AUTOSAR XML (schema 4-3-0)
package /MICROSAR/NvM_swc/DataTypes
  impl type NvM_RequestResultType: compu {0=NVM_REQ_OK, 1=NVM_REQ_NOT_OK, 2=NVM_REQ_PENDING, 3=NVM_REQ_INTEGRITY_FAILED, 4=NVM_REQ_BLOCK_SKIPPED, 5=NVM_REQ_NV_INVALIDATED, 6=NVM_REQ_CANCELED, 7=NVM_REQ_REDUNDANCY_FAILED, 8=NVM_REQ_RESTORED_FROM_ROM}, implementation-data-type=uint8
  impl type NvM_BlockIdType: range raw 1..32767, implementation-data-type=uint16
  impl type NvM_ServiceIdType: compu {6=NVM_READ_BLOCK, 7=NVM_WRITE_BLOCK, 8=NVM_RESTORE_BLOCK_DEFAULTS, 9=NVM_ERASE_BLOCK, 11=NVM_INVALIDATE_NV_BLOCK, 12=NVM_READ_ALL}, implementation-data-type=uint8
package /MICROSAR/NvM_swc/Interfaces
  6 x client server interface, all with is-service=true, service-kind=NON-VOLATILE-RAM-MANAGER:
    NvMAdministration
      operation SetBlockProtection: possible-error=NvMAdministration/E_NOT_OK
        arg ProtectionEnabled: type=boolean, direction=IN
      error E_NOT_OK: error-code=1
    NvMService_AC3_SRBS
      6 x operation, all with possible-error=NvMService_AC3_SRBS/E_NOT_OK:
        GetErrorStatus
          arg ErrorStatus: type=NvM_RequestResultType, direction=OUT
        SetRamBlockStatus
          arg RamBlockStatus: type=boolean, direction=IN
        ReadBlock
          arg DstPtr: type=dtRef_VOID, direction=IN
        WriteBlock
          arg SrcPtr: type=dtRef_const_VOID, direction=IN
        InvalidateNvBlock
        EraseBlock
      error E_NOT_OK: error-code=1
    NvMNotifyJobFinished
      operation JobFinished
        arg ServiceId: type=NvM_ServiceIdType, direction=IN
        arg JobResult: type=NvM_RequestResultType, direction=IN
    NvMService_AC3_SRBS_Defs
      7 x operation, all with possible-error=NvMService_AC3_SRBS_Defs/E_NOT_OK:
        GetErrorStatus
          arg ErrorStatus: type=NvM_RequestResultType, direction=OUT
        SetRamBlockStatus
          arg RamBlockStatus: type=boolean, direction=IN
        ReadBlock
          arg DstPtr: type=dtRef_VOID, direction=IN
        WriteBlock
          arg SrcPtr: type=dtRef_const_VOID, direction=IN
        RestoreBlockDefaults
          arg DstPtr: type=dtRef_VOID, direction=IN
        InvalidateNvBlock
        EraseBlock
      error E_NOT_OK: error-code=1
    NvMNotifyInitBlock
      operation InitBlock
    NvMService_AC3_SRBS_DS
      8 x operation, all with possible-error=NvMService_AC3_SRBS_DS/E_NOT_OK:
        GetErrorStatus
          arg ErrorStatus: type=NvM_RequestResultType, direction=OUT
        SetRamBlockStatus
          arg RamBlockStatus: type=boolean, direction=IN
        ReadBlock
          arg DstPtr: type=dtRef_VOID, direction=IN
        WriteBlock
          arg SrcPtr: type=dtRef_const_VOID, direction=IN
        SetDataIndex
          arg DataIndex: type=uint8, direction=IN
        GetDataIndex
          arg DataIndex: type=uint8, direction=OUT
        InvalidateNvBlock
        EraseBlock
      error E_NOT_OK: error-code=1
package /MICROSAR/NvM_swc/ComponentTypes
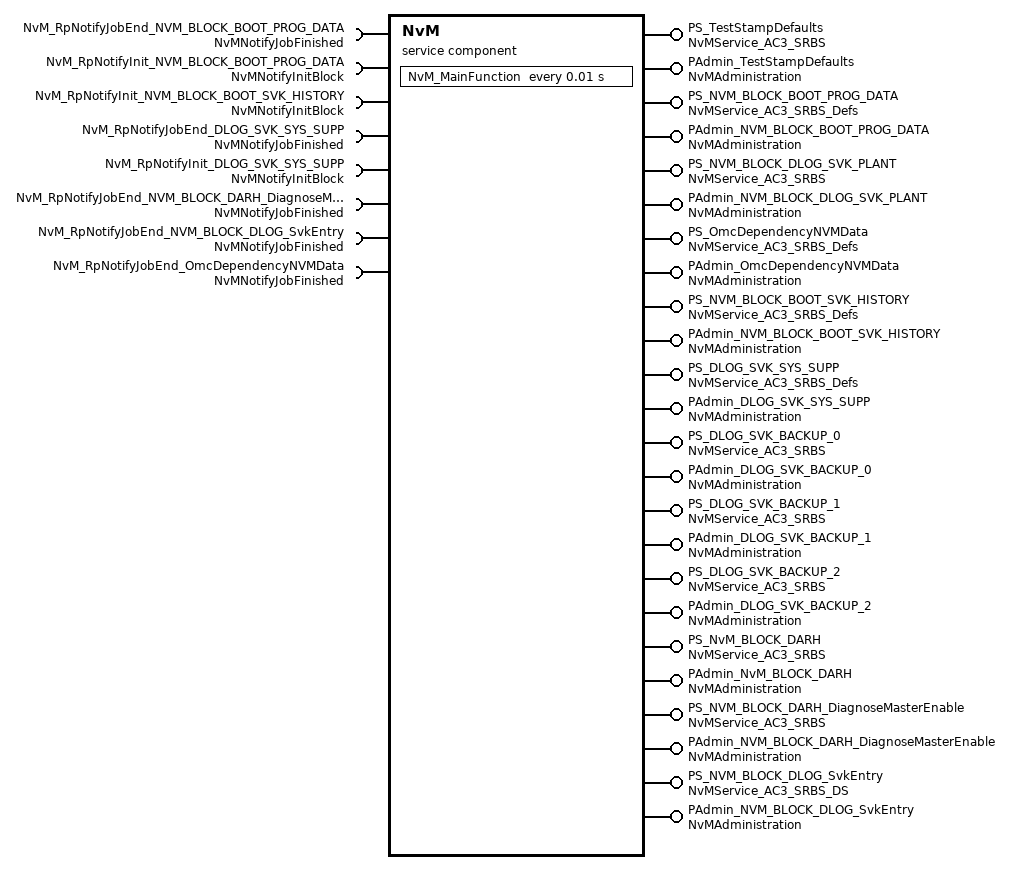
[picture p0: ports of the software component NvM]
  service sw component type NvM: category=SERVICE_COMPONENT
    4 x provide port:
      PS_TestStampDefaults: provided-interface=NvMService_AC3_SRBS
      PAdmin_TestStampDefaults: provided-interface=NvMAdministration
      PS_NVM_BLOCK_BOOT_PROG_DATA: provided-interface=NvMService_AC3_SRBS_Defs
      PAdmin_NVM_BLOCK_BOOT_PROG_DATA: provided-interface=NvMAdministration
    require port NvM_RpNotifyJobEnd_NVM_BLOCK_BOOT_PROG_DATA: required-interface=NvMNotifyJobFinished
    require port NvM_RpNotifyInit_NVM_BLOCK_BOOT_PROG_DATA: required-interface=NvMNotifyInitBlock
    6 x provide port:
      PS_NVM_BLOCK_DLOG_SVK_PLANT: provided-interface=NvMService_AC3_SRBS
      PAdmin_NVM_BLOCK_DLOG_SVK_PLANT: provided-interface=NvMAdministration
      PS_OmcDependencyNVMData: provided-interface=NvMService_AC3_SRBS_Defs
      PAdmin_OmcDependencyNVMData: provided-interface=NvMAdministration
      PS_NVM_BLOCK_BOOT_SVK_HISTORY: provided-interface=NvMService_AC3_SRBS_Defs
      PAdmin_NVM_BLOCK_BOOT_SVK_HISTORY: provided-interface=NvMAdministration
    require port NvM_RpNotifyInit_NVM_BLOCK_BOOT_SVK_HISTORY: required-interface=NvMNotifyInitBlock
    provide port PS_DLOG_SVK_SYS_SUPP: provided-interface=NvMService_AC3_SRBS_Defs
    provide port PAdmin_DLOG_SVK_SYS_SUPP: provided-interface=NvMAdministration
    require port NvM_RpNotifyJobEnd_DLOG_SVK_SYS_SUPP: required-interface=NvMNotifyJobFinished
    require port NvM_RpNotifyInit_DLOG_SVK_SYS_SUPP: required-interface=NvMNotifyInitBlock
    10 x provide port:
      PS_DLOG_SVK_BACKUP_0: provided-interface=NvMService_AC3_SRBS
      PAdmin_DLOG_SVK_BACKUP_0: provided-interface=NvMAdministration
      PS_DLOG_SVK_BACKUP_1: provided-interface=NvMService_AC3_SRBS
      PAdmin_DLOG_SVK_BACKUP_1: provided-interface=NvMAdministration
      PS_DLOG_SVK_BACKUP_2: provided-interface=NvMService_AC3_SRBS
      PAdmin_DLOG_SVK_BACKUP_2: provided-interface=NvMAdministration
      PS_NvM_BLOCK_DARH: provided-interface=NvMService_AC3_SRBS
      PAdmin_NvM_BLOCK_DARH: provided-interface=NvMAdministration
      PS_NVM_BLOCK_DARH_DiagnoseMasterEnable: provided-interface=NvMService_AC3_SRBS
      PAdmin_NVM_BLOCK_DARH_DiagnoseMasterEnable: provided-interface=NvMAdministration
    require port NvM_RpNotifyJobEnd_NVM_BLOCK_DARH_DiagnoseMasterEnable: required-interface=NvMNotifyJobFinished
    provide port PS_NVM_BLOCK_DLOG_SvkEntry: provided-interface=NvMService_AC3_SRBS_DS
    provide port PAdmin_NVM_BLOCK_DLOG_SvkEntry: provided-interface=NvMAdministration
    require port NvM_RpNotifyJobEnd_NVM_BLOCK_DLOG_SvkEntry: required-interface=NvMNotifyJobFinished
    require port NvM_RpNotifyJobEnd_OmcDependencyNVMData: required-interface=NvMNotifyJobFinished
    behavior NvMInternalBehavior: handle-termination-and-restart=NO-SUPPORT
      timing event Timer_NvM_MainFunction: start-on-event=NvM_MainFunction, period=0.01
      90 x operation invoked event:
        OpEventGetErrorStatus_GetErrorStatus_PS_TestStampDefaults: start-on-event=GetErrorStatus, operation=PS_TestStampDefaults.GetErrorStatus
        OpEventGetErrorStatus_GetErrorStatus_PS_NVM_BLOCK_BOOT_PROG_DATA: start-on-event=GetErrorStatus, operation=PS_NVM_BLOCK_BOOT_PROG_DATA.GetErrorStatus
        OpEventGetErrorStatus_GetErrorStatus_PS_NVM_BLOCK_DLOG_SVK_PLANT: start-on-event=GetErrorStatus, operation=PS_NVM_BLOCK_DLOG_SVK_PLANT.GetErrorStatus
        OpEventGetErrorStatus_GetErrorStatus_PS_OmcDependencyNVMData: start-on-event=GetErrorStatus, operation=PS_OmcDependencyNVMData.GetErrorStatus
        OpEventGetErrorStatus_GetErrorStatus_PS_NVM_BLOCK_BOOT_SVK_HISTORY: start-on-event=GetErrorStatus, operation=PS_NVM_BLOCK_BOOT_SVK_HISTORY.GetErrorStatus
        OpEventSetRamBlockStatus_SetRamBlockStatus_PS_TestStampDefaults: start-on-event=SetRamBlockStatus, operation=PS_TestStampDefaults.SetRamBlockStatus
        OpEventSetRamBlockStatus_SetRamBlockStatus_PS_NVM_BLOCK_BOOT_PROG_DATA: start-on-event=SetRamBlockStatus, operation=PS_NVM_BLOCK_BOOT_PROG_DATA.SetRamBlockStatus
        OpEventSetRamBlockStatus_SetRamBlockStatus_PS_NVM_BLOCK_DLOG_SVK_PLANT: start-on-event=SetRamBlockStatus, operation=PS_NVM_BLOCK_DLOG_SVK_PLANT.SetRamBlockStatus
        OpEventSetRamBlockStatus_SetRamBlockStatus_PS_OmcDependencyNVMData: start-on-event=SetRamBlockStatus, operation=PS_OmcDependencyNVMData.SetRamBlockStatus
        OpEventSetRamBlockStatus_SetRamBlockStatus_PS_NVM_BLOCK_BOOT_SVK_HISTORY: start-on-event=SetRamBlockStatus, operation=PS_NVM_BLOCK_BOOT_SVK_HISTORY.SetRamBlockStatus
        OpEventReadBlock_ReadBlock_PS_TestStampDefaults: start-on-event=ReadBlock, operation=PS_TestStampDefaults.ReadBlock
        OpEventReadBlock_ReadBlock_PS_NVM_BLOCK_BOOT_PROG_DATA: start-on-event=ReadBlock, operation=PS_NVM_BLOCK_BOOT_PROG_DATA.ReadBlock
        OpEventReadBlock_ReadBlock_PS_NVM_BLOCK_DLOG_SVK_PLANT: start-on-event=ReadBlock, operation=PS_NVM_BLOCK_DLOG_SVK_PLANT.ReadBlock
        OpEventReadBlock_ReadBlock_PS_OmcDependencyNVMData: start-on-event=ReadBlock, operation=PS_OmcDependencyNVMData.ReadBlock
        OpEventReadBlock_ReadBlock_PS_NVM_BLOCK_BOOT_SVK_HISTORY: start-on-event=ReadBlock, operation=PS_NVM_BLOCK_BOOT_SVK_HISTORY.ReadBlock
        OpEventWriteBlock_WriteBlock_PS_TestStampDefaults: start-on-event=WriteBlock, operation=PS_TestStampDefaults.WriteBlock
        OpEventWriteBlock_WriteBlock_PS_NVM_BLOCK_BOOT_PROG_DATA: start-on-event=WriteBlock, operation=PS_NVM_BLOCK_BOOT_PROG_DATA.WriteBlock
        OpEventWriteBlock_WriteBlock_PS_NVM_BLOCK_DLOG_SVK_PLANT: start-on-event=WriteBlock, operation=PS_NVM_BLOCK_DLOG_SVK_PLANT.WriteBlock
        OpEventWriteBlock_WriteBlock_PS_OmcDependencyNVMData: start-on-event=WriteBlock, operation=PS_OmcDependencyNVMData.WriteBlock
        OpEventWriteBlock_WriteBlock_PS_NVM_BLOCK_BOOT_SVK_HISTORY: start-on-event=WriteBlock, operation=PS_NVM_BLOCK_BOOT_SVK_HISTORY.WriteBlock
        OpEventInvalidateNvBlock_InvalidateNvBlock_PS_TestStampDefaults: start-on-event=InvalidateNvBlock, operation=PS_TestStampDefaults.InvalidateNvBlock
        OpEventInvalidateNvBlock_InvalidateNvBlock_PS_NVM_BLOCK_BOOT_PROG_DATA: start-on-event=InvalidateNvBlock, operation=PS_NVM_BLOCK_BOOT_PROG_DATA.InvalidateNvBlock
        OpEventInvalidateNvBlock_InvalidateNvBlock_PS_NVM_BLOCK_DLOG_SVK_PLANT: start-on-event=InvalidateNvBlock, operation=PS_NVM_BLOCK_DLOG_SVK_PLANT.InvalidateNvBlock
        OpEventInvalidateNvBlock_InvalidateNvBlock_PS_OmcDependencyNVMData: start-on-event=InvalidateNvBlock, operation=PS_OmcDependencyNVMData.InvalidateNvBlock
        OpEventInvalidateNvBlock_InvalidateNvBlock_PS_NVM_BLOCK_BOOT_SVK_HISTORY: start-on-event=InvalidateNvBlock, operation=PS_NVM_BLOCK_BOOT_SVK_HISTORY.InvalidateNvBlock
        OpEventEraseBlock_EraseBlock_PS_TestStampDefaults: start-on-event=EraseBlock, operation=PS_TestStampDefaults.EraseBlock
        OpEventEraseBlock_EraseBlock_PS_NVM_BLOCK_BOOT_PROG_DATA: start-on-event=EraseBlock, operation=PS_NVM_BLOCK_BOOT_PROG_DATA.EraseBlock
        OpEventEraseBlock_EraseBlock_PS_NVM_BLOCK_DLOG_SVK_PLANT: start-on-event=EraseBlock, operation=PS_NVM_BLOCK_DLOG_SVK_PLANT.EraseBlock
        OpEventEraseBlock_EraseBlock_PS_OmcDependencyNVMData: start-on-event=EraseBlock, operation=PS_OmcDependencyNVMData.EraseBlock
        OpEventEraseBlock_EraseBlock_PS_NVM_BLOCK_BOOT_SVK_HISTORY: start-on-event=EraseBlock, operation=PS_NVM_BLOCK_BOOT_SVK_HISTORY.EraseBlock
        OpEventSetBlockProtection_SetBlockProtection_PAdmin_TestStampDefaults: start-on-event=SetBlockProtection, operation=PAdmin_TestStampDefaults.SetBlockProtection
        OpEventSetBlockProtection_SetBlockProtection_PAdmin_NVM_BLOCK_BOOT_PROG_DATA: start-on-event=SetBlockProtection, operation=PAdmin_NVM_BLOCK_BOOT_PROG_DATA.SetBlockProtection
        OpEventSetBlockProtection_SetBlockProtection_PAdmin_NVM_BLOCK_DLOG_SVK_PLANT: start-on-event=SetBlockProtection, operation=PAdmin_NVM_BLOCK_DLOG_SVK_PLANT.SetBlockProtection
        OpEventSetBlockProtection_SetBlockProtection_PAdmin_OmcDependencyNVMData: start-on-event=SetBlockProtection, operation=PAdmin_OmcDependencyNVMData.SetBlockProtection
        OpEventSetBlockProtection_SetBlockProtection_PAdmin_NVM_BLOCK_BOOT_SVK_HISTORY: start-on-event=SetBlockProtection, operation=PAdmin_NVM_BLOCK_BOOT_SVK_HISTORY.SetBlockProtection
        OpEventRestoreBlockDefaults_RestoreBlockDefaults_PS_NVM_BLOCK_BOOT_PROG_DATA: start-on-event=RestoreBlockDefaults, operation=PS_NVM_BLOCK_BOOT_PROG_DATA.RestoreBlockDefaults
        OpEventRestoreBlockDefaults_RestoreBlockDefaults_PS_OmcDependencyNVMData: start-on-event=RestoreBlockDefaults, operation=PS_OmcDependencyNVMData.RestoreBlockDefaults
        OpEventRestoreBlockDefaults_RestoreBlockDefaults_PS_NVM_BLOCK_BOOT_SVK_HISTORY: start-on-event=RestoreBlockDefaults, operation=PS_NVM_BLOCK_BOOT_SVK_HISTORY.RestoreBlockDefaults
        OpEventGetErrorStatus_GetErrorStatus_PS_DLOG_SVK_SYS_SUPP: start-on-event=GetErrorStatus, operation=PS_DLOG_SVK_SYS_SUPP.GetErrorStatus
        OpEventGetErrorStatus_GetErrorStatus_PS_DLOG_SVK_BACKUP_{0..2}: start-on-event=GetErrorStatus, operation=PS_DLOG_SVK_BACKUP_{0..2}.GetErrorStatus
        OpEventSetRamBlockStatus_SetRamBlockStatus_PS_DLOG_SVK_SYS_SUPP: start-on-event=SetRamBlockStatus, operation=PS_DLOG_SVK_SYS_SUPP.SetRamBlockStatus
        OpEventSetRamBlockStatus_SetRamBlockStatus_PS_DLOG_SVK_BACKUP_{0..2}: start-on-event=SetRamBlockStatus, operation=PS_DLOG_SVK_BACKUP_{0..2}.SetRamBlockStatus
        OpEventReadBlock_ReadBlock_PS_DLOG_SVK_SYS_SUPP: start-on-event=ReadBlock, operation=PS_DLOG_SVK_SYS_SUPP.ReadBlock
        OpEventReadBlock_ReadBlock_PS_DLOG_SVK_BACKUP_{0..2}: start-on-event=ReadBlock, operation=PS_DLOG_SVK_BACKUP_{0..2}.ReadBlock
        OpEventWriteBlock_WriteBlock_PS_DLOG_SVK_SYS_SUPP: start-on-event=WriteBlock, operation=PS_DLOG_SVK_SYS_SUPP.WriteBlock
        OpEventWriteBlock_WriteBlock_PS_DLOG_SVK_BACKUP_{0..2}: start-on-event=WriteBlock, operation=PS_DLOG_SVK_BACKUP_{0..2}.WriteBlock
        OpEventRestoreBlockDefaults_RestoreBlockDefaults_PS_DLOG_SVK_SYS_SUPP: start-on-event=RestoreBlockDefaults, operation=PS_DLOG_SVK_SYS_SUPP.RestoreBlockDefaults
        OpEventInvalidateNvBlock_InvalidateNvBlock_PS_DLOG_SVK_SYS_SUPP: start-on-event=InvalidateNvBlock, operation=PS_DLOG_SVK_SYS_SUPP.InvalidateNvBlock
        OpEventInvalidateNvBlock_InvalidateNvBlock_PS_DLOG_SVK_BACKUP_{0..2}: start-on-event=InvalidateNvBlock, operation=PS_DLOG_SVK_BACKUP_{0..2}.InvalidateNvBlock
        OpEventEraseBlock_EraseBlock_PS_DLOG_SVK_SYS_SUPP: start-on-event=EraseBlock, operation=PS_DLOG_SVK_SYS_SUPP.EraseBlock
        OpEventEraseBlock_EraseBlock_PS_DLOG_SVK_BACKUP_{0..2}: start-on-event=EraseBlock, operation=PS_DLOG_SVK_BACKUP_{0..2}.EraseBlock
        OpEventSetBlockProtection_SetBlockProtection_PAdmin_DLOG_SVK_SYS_SUPP: start-on-event=SetBlockProtection, operation=PAdmin_DLOG_SVK_SYS_SUPP.SetBlockProtection
        OpEventSetBlockProtection_SetBlockProtection_PAdmin_DLOG_SVK_BACKUP_{0..2}: start-on-event=SetBlockProtection, operation=PAdmin_DLOG_SVK_BACKUP_{0..2}.SetBlockProtection
        OpEventGetErrorStatus_GetErrorStatus_PS_NvM_BLOCK_DARH: start-on-event=GetErrorStatus, operation=PS_NvM_BLOCK_DARH.GetErrorStatus
        OpEventGetErrorStatus_GetErrorStatus_PS_NVM_BLOCK_DARH_DiagnoseMasterEnable: start-on-event=GetErrorStatus, operation=PS_NVM_BLOCK_DARH_DiagnoseMasterEnable.GetErrorStatus
        OpEventSetRamBlockStatus_SetRamBlockStatus_PS_NvM_BLOCK_DARH: start-on-event=SetRamBlockStatus, operation=PS_NvM_BLOCK_DARH.SetRamBlockStatus
        OpEventSetRamBlockStatus_SetRamBlockStatus_PS_NVM_BLOCK_DARH_DiagnoseMasterEnable: start-on-event=SetRamBlockStatus, operation=PS_NVM_BLOCK_DARH_DiagnoseMasterEnable.SetRamBlockStatus
        OpEventReadBlock_ReadBlock_PS_NvM_BLOCK_DARH: start-on-event=ReadBlock, operation=PS_NvM_BLOCK_DARH.ReadBlock
        OpEventReadBlock_ReadBlock_PS_NVM_BLOCK_DARH_DiagnoseMasterEnable: start-on-event=ReadBlock, operation=PS_NVM_BLOCK_DARH_DiagnoseMasterEnable.ReadBlock
        OpEventWriteBlock_WriteBlock_PS_NvM_BLOCK_DARH: start-on-event=WriteBlock, operation=PS_NvM_BLOCK_DARH.WriteBlock
        OpEventWriteBlock_WriteBlock_PS_NVM_BLOCK_DARH_DiagnoseMasterEnable: start-on-event=WriteBlock, operation=PS_NVM_BLOCK_DARH_DiagnoseMasterEnable.WriteBlock
        OpEventInvalidateNvBlock_InvalidateNvBlock_PS_NvM_BLOCK_DARH: start-on-event=InvalidateNvBlock, operation=PS_NvM_BLOCK_DARH.InvalidateNvBlock
        OpEventInvalidateNvBlock_InvalidateNvBlock_PS_NVM_BLOCK_DARH_DiagnoseMasterEnable: start-on-event=InvalidateNvBlock, operation=PS_NVM_BLOCK_DARH_DiagnoseMasterEnable.InvalidateNvBlock
        OpEventEraseBlock_EraseBlock_PS_NvM_BLOCK_DARH: start-on-event=EraseBlock, operation=PS_NvM_BLOCK_DARH.EraseBlock
        OpEventEraseBlock_EraseBlock_PS_NVM_BLOCK_DARH_DiagnoseMasterEnable: start-on-event=EraseBlock, operation=PS_NVM_BLOCK_DARH_DiagnoseMasterEnable.EraseBlock
        OpEventSetBlockProtection_SetBlockProtection_PAdmin_NvM_BLOCK_DARH: start-on-event=SetBlockProtection, operation=PAdmin_NvM_BLOCK_DARH.SetBlockProtection
        OpEventSetBlockProtection_SetBlockProtection_PAdmin_NVM_BLOCK_DARH_DiagnoseMasterEnable: start-on-event=SetBlockProtection, operation=PAdmin_NVM_BLOCK_DARH_DiagnoseMasterEnable.SetBlockProtection
        OpEventGetErrorStatus_GetErrorStatus_PS_NVM_BLOCK_DLOG_SvkEntry: start-on-event=GetErrorStatus, operation=PS_NVM_BLOCK_DLOG_SvkEntry.GetErrorStatus
        OpEventSetRamBlockStatus_SetRamBlockStatus_PS_NVM_BLOCK_DLOG_SvkEntry: start-on-event=SetRamBlockStatus, operation=PS_NVM_BLOCK_DLOG_SvkEntry.SetRamBlockStatus
        OpEventReadBlock_ReadBlock_PS_NVM_BLOCK_DLOG_SvkEntry: start-on-event=ReadBlock, operation=PS_NVM_BLOCK_DLOG_SvkEntry.ReadBlock
        OpEventWriteBlock_WriteBlock_PS_NVM_BLOCK_DLOG_SvkEntry: start-on-event=WriteBlock, operation=PS_NVM_BLOCK_DLOG_SvkEntry.WriteBlock
        OpEventSetDataIndex_SetDataIndex_PS_NVM_BLOCK_DLOG_SvkEntry: start-on-event=SetDataIndex, operation=PS_NVM_BLOCK_DLOG_SvkEntry.SetDataIndex
        OpEventGetDataIndex_GetDataIndex_PS_NVM_BLOCK_DLOG_SvkEntry: start-on-event=GetDataIndex, operation=PS_NVM_BLOCK_DLOG_SvkEntry.GetDataIndex
        OpEventInvalidateNvBlock_InvalidateNvBlock_PS_NVM_BLOCK_DLOG_SvkEntry: start-on-event=InvalidateNvBlock, operation=PS_NVM_BLOCK_DLOG_SvkEntry.InvalidateNvBlock
        OpEventEraseBlock_EraseBlock_PS_NVM_BLOCK_DLOG_SvkEntry: start-on-event=EraseBlock, operation=PS_NVM_BLOCK_DLOG_SvkEntry.EraseBlock
        OpEventSetBlockProtection_SetBlockProtection_PAdmin_NVM_BLOCK_DLOG_SvkEntry: start-on-event=SetBlockProtection, operation=PAdmin_NVM_BLOCK_DLOG_SvkEntry.SetBlockProtection
      port-api-options:
        enable-take-address=true, indirect-api=false, port=NvM_RpNotifyJobEnd_NVM_BLOCK_BOOT_PROG_DATA
        enable-take-address=true, indirect-api=false, port=NvM_RpNotifyInit_NVM_BLOCK_BOOT_PROG_DATA
        enable-take-address=true, indirect-api=false, port=NvM_RpNotifyInit_NVM_BLOCK_BOOT_SVK_HISTORY
        enable-take-address=true, indirect-api=false, port=NvM_RpNotifyJobEnd_DLOG_SVK_SYS_SUPP
        enable-take-address=true, indirect-api=false, port=NvM_RpNotifyInit_DLOG_SVK_SYS_SUPP
        {enable-take-address=true, indirect-api=false, port-defined-argument-value{value=10, value-type=NvM_BlockIdType}, port=PS_NVM_BLOCK_BOOT_SVK_HISTORY}
        {enable-take-address=true, indirect-api=false, port-defined-argument-value{value=10, value-type=NvM_BlockIdType}, port=PAdmin_NVM_BLOCK_BOOT_SVK_HISTORY}
        {enable-take-address=true, indirect-api=false, port-defined-argument-value{value=3, value-type=NvM_BlockIdType}, port=PS_DLOG_SVK_BACKUP_0}
        {enable-take-address=true, indirect-api=false, port-defined-argument-value{value=3, value-type=NvM_BlockIdType}, port=PAdmin_DLOG_SVK_BACKUP_0}
        {enable-take-address=true, indirect-api=false, port-defined-argument-value{value=4, value-type=NvM_BlockIdType}, port=PS_DLOG_SVK_BACKUP_1}
        {enable-take-address=true, indirect-api=false, port-defined-argument-value{value=4, value-type=NvM_BlockIdType}, port=PAdmin_DLOG_SVK_BACKUP_1}
        {enable-take-address=true, indirect-api=false, port-defined-argument-value{value=5, value-type=NvM_BlockIdType}, port=PS_DLOG_SVK_BACKUP_2}
        {enable-take-address=true, indirect-api=false, port-defined-argument-value{value=5, value-type=NvM_BlockIdType}, port=PAdmin_DLOG_SVK_BACKUP_2}
        {enable-take-address=true, indirect-api=false, port-defined-argument-value{value=11, value-type=NvM_BlockIdType}, port=PS_NVM_BLOCK_DARH_DiagnoseMasterEnable}
        {enable-take-address=true, indirect-api=false, port-defined-argument-value{value=11, value-type=NvM_BlockIdType}, port=PAdmin_NVM_BLOCK_DARH_DiagnoseMasterEnable}
        enable-take-address=true, indirect-api=false, port=NvM_RpNotifyJobEnd_NVM_BLOCK_DARH_DiagnoseMasterEnable
        {enable-take-address=true, indirect-api=false, port-defined-argument-value{value=13, value-type=NvM_BlockIdType}, port=PS_NVM_BLOCK_BOOT_PROG_DATA}
        {enable-take-address=true, indirect-api=false, port-defined-argument-value{value=13, value-type=NvM_BlockIdType}, port=PAdmin_NVM_BLOCK_BOOT_PROG_DATA}
        enable-take-address=true, indirect-api=false, port=NvM_RpNotifyJobEnd_NVM_BLOCK_DLOG_SvkEntry
        {enable-take-address=true, indirect-api=false, port-defined-argument-value{value=27, value-type=NvM_BlockIdType}, port=PS_NVM_BLOCK_DLOG_SvkEntry}
        {enable-take-address=true, indirect-api=false, port-defined-argument-value{value=27, value-type=NvM_BlockIdType}, port=PAdmin_NVM_BLOCK_DLOG_SvkEntry}
        {enable-take-address=true, indirect-api=false, port-defined-argument-value{value=25, value-type=NvM_BlockIdType}, port=PS_NvM_BLOCK_DARH}
        {enable-take-address=true, indirect-api=false, port-defined-argument-value{value=25, value-type=NvM_BlockIdType}, port=PAdmin_NvM_BLOCK_DARH}
        {enable-take-address=true, indirect-api=false, port-defined-argument-value{value=16, value-type=NvM_BlockIdType}, port=PS_DLOG_SVK_SYS_SUPP}
        {enable-take-address=true, indirect-api=false, port-defined-argument-value{value=16, value-type=NvM_BlockIdType}, port=PAdmin_DLOG_SVK_SYS_SUPP}
        {enable-take-address=true, indirect-api=false, port-defined-argument-value{value=26, value-type=NvM_BlockIdType}, port=PS_TestStampDefaults}
        {enable-take-address=true, indirect-api=false, port-defined-argument-value{value=26, value-type=NvM_BlockIdType}, port=PAdmin_TestStampDefaults}
        {enable-take-address=true, indirect-api=false, port-defined-argument-value{value=18, value-type=NvM_BlockIdType}, port=PS_NVM_BLOCK_DLOG_SVK_PLANT}
        {enable-take-address=true, indirect-api=false, port-defined-argument-value{value=18, value-type=NvM_BlockIdType}, port=PAdmin_NVM_BLOCK_DLOG_SVK_PLANT}
        {enable-take-address=true, indirect-api=false, port-defined-argument-value{value=24, value-type=NvM_BlockIdType}, port=PS_OmcDependencyNVMData}
        {enable-take-address=true, indirect-api=false, port-defined-argument-value{value=24, value-type=NvM_BlockIdType}, port=PAdmin_OmcDependencyNVMData}
        enable-take-address=true, indirect-api=false, port=NvM_RpNotifyJobEnd_OmcDependencyNVMData
      11 x runnable:
        NvM_MainFunction
          8 x sync call, all with timeout=0:
            OpServerCallNvM_MainFunction_JobFinished_NvM_RpNotifyJobEnd_NVM_BLOCK_BOOT_PROG_DATA: operation=NvM_RpNotifyJobEnd_NVM_BLOCK_BOOT_PROG_DATA.JobFinished
            OpServerCallNvM_MainFunction_InitBlock_NvM_RpNotifyInit_NVM_BLOCK_BOOT_PROG_DATA: operation=NvM_RpNotifyInit_NVM_BLOCK_BOOT_PROG_DATA.InitBlock
            OpServerCallNvM_MainFunction_InitBlock_NvM_RpNotifyInit_NVM_BLOCK_BOOT_SVK_HISTORY: operation=NvM_RpNotifyInit_NVM_BLOCK_BOOT_SVK_HISTORY.InitBlock
            OpServerCallNvM_MainFunction_JobFinished_NvM_RpNotifyJobEnd_DLOG_SVK_SYS_SUPP: operation=NvM_RpNotifyJobEnd_DLOG_SVK_SYS_SUPP.JobFinished
            OpServerCallNvM_MainFunction_InitBlock_NvM_RpNotifyInit_DLOG_SVK_SYS_SUPP: operation=NvM_RpNotifyInit_DLOG_SVK_SYS_SUPP.InitBlock
            OpServerCallNvM_MainFunction_JobFinished_NvM_RpNotifyJobEnd_NVM_BLOCK_DARH_DiagnoseMasterEnable: operation=NvM_RpNotifyJobEnd_NVM_BLOCK_DARH_DiagnoseMasterEnable.JobFinished
            OpServerCallNvM_MainFunction_JobFinished_NvM_RpNotifyJobEnd_NVM_BLOCK_DLOG_SvkEntry: operation=NvM_RpNotifyJobEnd_NVM_BLOCK_DLOG_SvkEntry.JobFinished
            OpServerCallNvM_MainFunction_JobFinished_NvM_RpNotifyJobEnd_OmcDependencyNVMData: operation=NvM_RpNotifyJobEnd_OmcDependencyNVMData.JobFinished
        GetErrorStatus: can-be-invoked-concurrently=true, symbol=NvM_GetErrorStatus
        SetRamBlockStatus: can-be-invoked-concurrently=true, symbol=NvM_SetRamBlockStatus
        ReadBlock: can-be-invoked-concurrently=true, symbol=NvM_ReadBlock
        WriteBlock: can-be-invoked-concurrently=true, symbol=NvM_WriteBlock
        InvalidateNvBlock: can-be-invoked-concurrently=true, symbol=NvM_InvalidateNvBlock
        EraseBlock: can-be-invoked-concurrently=true, symbol=NvM_EraseNvBlock
        SetBlockProtection: can-be-invoked-concurrently=true, symbol=NvM_SetBlockProtection
        RestoreBlockDefaults: can-be-invoked-concurrently=true, symbol=NvM_RestoreBlockDefaults
        SetDataIndex: can-be-invoked-concurrently=true, symbol=NvM_SetDataIndex
        GetDataIndex: can-be-invoked-concurrently=true, symbol=NvM_GetDataIndex
  swc implementation NvMImplementation: programming-language=C, behavior=NvMInternalBehavior
